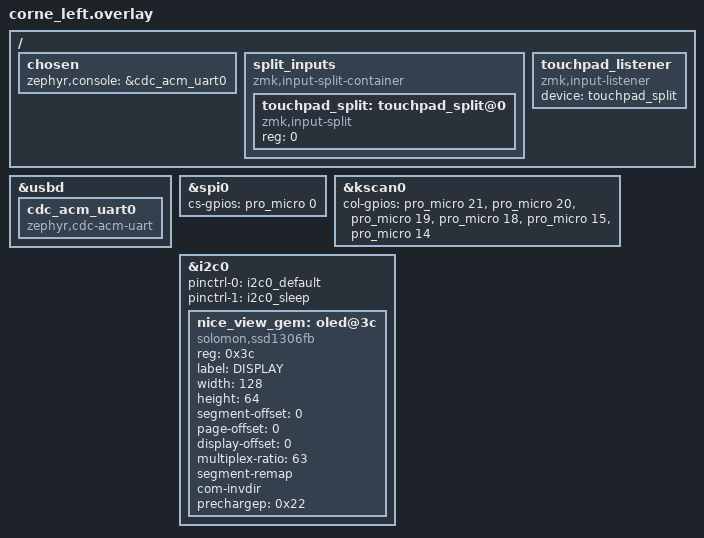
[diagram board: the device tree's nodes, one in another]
/*
 * Copyright (c) 2020 Pete Johanson
 *
 * SPDX-License-Identifier: MIT
 */

#include "corne.dtsi"
#include <dt-bindings/zmk/pointing.h>
// #include <dt-bindings/zmk/input_transform.h>

// #include <dt-bindings/pinctrl/nrf-pinctrl.h>
// #define MOUSE_I2C_PIN_SCL_PINCTRL <NRF_PSEL(TWIM_SCL, 0, 20)>
// #define MOUSE_I2C_PIN_SDA_PINCTRL <NRF_PSEL(TWIM_SDA, 0, 17)>

/ {
    chosen {
        zephyr,console = &cdc_acm_uart0;
    };
};

&usbd {
    status = "okay";
    cdc_acm_uart0: cdc_acm_uart0 {
        compatible = "zephyr,cdc-acm-uart";
    };
};

&spi0 {
    cs-gpios = <&pro_micro 0 GPIO_ACTIVE_HIGH>;
};

&kscan0 {
    col-gpios
        = <&pro_micro 21 GPIO_ACTIVE_HIGH>
        , <&pro_micro 20 GPIO_ACTIVE_HIGH>
        , <&pro_micro 19 GPIO_ACTIVE_HIGH>
        , <&pro_micro 18 GPIO_ACTIVE_HIGH>
        , <&pro_micro 15 GPIO_ACTIVE_HIGH>
        , <&pro_micro 14 GPIO_ACTIVE_HIGH>
        ;
};

// &pinctrl {
//    i2c0_default: i2c0_default {
//        group1 {
//            psels = MOUSE_I2C_PIN_SDA_PINCTRL, MOUSE_I2C_PIN_SCL_PINCTRL;
//            bias-pull-up;
//        };
//    };
//    i2c0_sleep: i2c0_sleep {
//        group1 {
//            psels = MOUSE_I2C_PIN_SDA_PINCTRL, MOUSE_I2C_PIN_SCL_PINCTRL;
//            low-power-enable;
//        };
//    };
// };

&i2c0 {
    status = "okay";
    pinctrl-0 = <&i2c0_default>;
    pinctrl-1 = <&i2c0_sleep>;
    pinctrl-names = "default", "sleep";

    /* nice!view-gem Display */
    nice_view_gem: oled@3c {
        compatible = "solomon,ssd1306fb";
        reg = <0x3c>;
        label = "DISPLAY";
        width = <128>;
        height = <64>;
        segment-offset = <0>;
        page-offset = <0>;
        display-offset = <0>;
        multiplex-ratio = <63>;
        segment-remap;
        com-invdir;
        prechargep = <0x22>;
    };
};

/ {
    split_inputs {
        compatible = "zmk,input-split-container";
        #address-cells = <1>;
        #size-cells = <0>;

        /* Matching ID from the peripheral */
        touchpad_split: touchpad_split@0 {
            compatible = "zmk,input-split";
            reg = <0>;

        };
    };

    /* Listener on central side to handle the split events */
    touchpad_listener {
        compatible = "zmk,input-listener";
        device = <&touchpad_split>;
        /* XY Scaler set to 1:1 ensures we see raw data in the logs */
        // input-processors = <&zip_xy_scaler 1 1>;
    };
};


